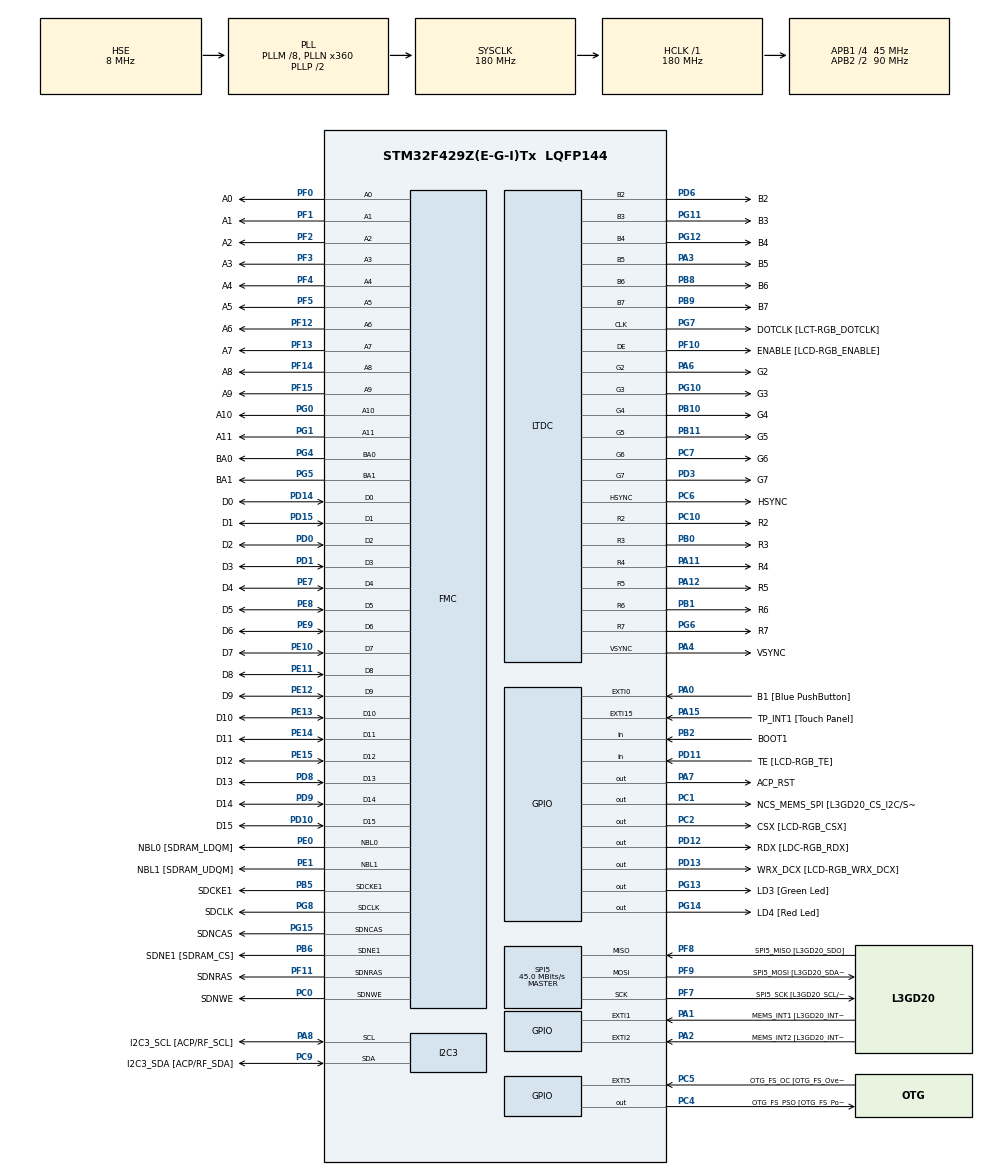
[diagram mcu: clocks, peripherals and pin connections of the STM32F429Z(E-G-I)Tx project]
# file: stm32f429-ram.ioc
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DMA2D.ColorMode=DMA2D_OUTPUT_RGB565
FMC.CASLatency1=FMC_SDRAM_CAS_LATENCY_3
FMC.ColumnBitsNumber1=FMC_SDRAM_COLUMN_BITS_NUM_8
FMC.ReadPipeDelay1=FMC_SDRAM_RPIPE_DELAY_2
FMC.ReadPipeDelay2=FMC_SDRAM_RPIPE_DELAY_2
FMC.SDClockPeriod1=FMC_SDRAM_CLOCK_PERIOD_2
FMC.SDClockPeriod2=FMC_SDRAM_CLOCK_PERIOD_2
FMC.WriteProtection1=FMC_SDRAM_WRITE_PROTECTION_ENABLE
LTDC.ActiveW=320
Mcu.Family=STM32F4
Mcu.Name=STM32F429Z(E-G-I)Tx
Mcu.Package=LQFP144
NVIC.PriorityGroup=NVIC_PRIORITYGROUP_0
PA0/WKUP.GPIO_Label=B1 [Blue PushButton]
PA0/WKUP.GPIO_ModeDefaultEXTI=GPIO_MODE_EVT_RISING
PA0/WKUP.GPIO_PuPd=GPIO_NOPULL
PA0/WKUP.Signal=GPXTI0
PA1.GPIO_Label=MEMS_INT1 [L3GD20_INT1]
PA1.GPIO_ModeDefaultEXTI=GPIO_MODE_EVT_RISING
PA1.GPIO_PuPd=GPIO_NOPULL
PA1.Signal=GPXTI1
PA11.GPIO_Label=R4
PA11.GPIO_Mode=GPIO_MODE_AF_PP
PA11.GPIO_PuPd=GPIO_NOPULL
PA11.GPIO_Speed=GPIO_SPEED_FREQ_LOW
PA11.Mode=RGB666
PA11.Signal=LTDC_R4
PA12.GPIO_Label=R5
PA12.GPIO_Mode=GPIO_MODE_AF_PP
PA12.GPIO_PuPd=GPIO_NOPULL
PA12.GPIO_Speed=GPIO_SPEED_FREQ_LOW
PA12.Mode=RGB666
PA12.Signal=LTDC_R5
PA13.GPIO_Label=SWDIO
PA13.Signal=SYS_JTMS-SWDIO
PA14.GPIO_Label=SWCLK
PA14.Signal=SYS_JTCK-SWCLK
PA15.GPIO_Label=TP_INT1 [Touch Panel]
PA15.GPIO_ModeDefaultEXTI=GPIO_MODE_EVT_RISING
PA15.GPIO_PuPd=GPIO_NOPULL
PA15.Signal=GPXTI15
PA2.GPIO_Label=MEMS_INT2 [L3GD20_INT2]
PA2.GPIO_ModeDefaultEXTI=GPIO_MODE_EVT_RISING
PA2.GPIO_PuPd=GPIO_NOPULL
PA2.Signal=GPXTI2
PA3.GPIO_Label=B5
PA3.GPIO_Mode=GPIO_MODE_AF_PP
PA3.GPIO_PuPd=GPIO_NOPULL
PA3.GPIO_Speed=GPIO_SPEED_FREQ_LOW
PA3.Mode=RGB666
PA3.Signal=LTDC_B5
PA4.GPIO_Label=VSYNC
PA4.GPIO_Mode=GPIO_MODE_AF_PP
PA4.GPIO_PuPd=GPIO_NOPULL
PA4.GPIO_Speed=GPIO_SPEED_FREQ_LOW
PA4.Mode=RGB666
PA4.Signal=LTDC_VSYNC
PA6.GPIO_Label=G2
PA6.GPIO_Mode=GPIO_MODE_AF_PP
PA6.GPIO_PuPd=GPIO_NOPULL
PA6.GPIO_Speed=GPIO_SPEED_FREQ_LOW
PA6.Mode=RGB666
PA6.Signal=LTDC_G2
PA7.GPIO_Label=ACP_RST
PA7.GPIO_Mode=GPIO_MODE_OUTPUT_PP
PA7.GPIO_PuPd=GPIO_NOPULL
PA7.GPIO_Speed=GPIO_SPEED_FREQ_LOW
PA7.Signal=GPIO_Output
PA8.GPIO_Label=I2C3_SCL [ACP/RF_SCL]
PA8.GPIO_Mode=GPIO_MODE_AF_OD
PA8.GPIO_PuPd=GPIO_NOPULL
PA8.GPIO_Speed=GPIO_SPEED_FREQ_LOW
PA8.Mode=I2C
PA8.Signal=I2C3_SCL
PB0.GPIO_Label=R3
PB0.GPIO_Mode=GPIO_MODE_AF_PP
PB0.GPIO_PuPd=GPIO_NOPULL
PB0.GPIO_Speed=GPIO_SPEED_FREQ_LOW
PB0.Mode=RGB666
PB0.Signal=LTDC_R3
PB1.GPIO_Label=R6
PB1.GPIO_Mode=GPIO_MODE_AF_PP
PB1.GPIO_PuPd=GPIO_NOPULL
PB1.GPIO_Speed=GPIO_SPEED_FREQ_LOW
PB1.Mode=RGB666
PB1.Signal=LTDC_R6
PB10.GPIO_Label=G4
PB10.GPIO_Mode=GPIO_MODE_AF_PP
PB10.GPIO_PuPd=GPIO_NOPULL
PB10.GPIO_Speed=GPIO_SPEED_FREQ_LOW
PB10.Mode=RGB666
PB10.Signal=LTDC_G4
PB11.GPIO_Label=G5
PB11.GPIO_Mode=GPIO_MODE_AF_PP
PB11.GPIO_PuPd=GPIO_NOPULL
PB11.GPIO_Speed=GPIO_SPEED_FREQ_LOW
PB11.Mode=RGB666
PB11.Signal=LTDC_G5
PB12.GPIO_Label=OTG_FS_ID
PB12.GPIO_Mode=GPIO_MODE_AF_PP
PB12.GPIO_PuPd=GPIO_NOPULL
PB12.GPIO_Speed=GPIO_SPEED_FREQ_LOW
PB12.Signal=USB_OTG_HS_ID
PB13.GPIO_Label=VBUS_FS
PB13.GPIO_Mode=GPIO_MODE_INPUT
PB13.GPIO_PuPd=GPIO_NOPULL
PB13.Signal=USB_OTG_HS_VBUS
PB14.GPIO_Label=OTG_FS_DM
PB14.GPIO_Mode=GPIO_MODE_AF_PP
PB14.GPIO_PuPd=GPIO_NOPULL
PB14.GPIO_Speed=GPIO_SPEED_FREQ_LOW
PB14.Signal=USB_OTG_HS_DM
PB15.GPIO_Label=OTG_FS_DP
PB15.GPIO_Mode=GPIO_MODE_AF_PP
PB15.GPIO_PuPd=GPIO_NOPULL
PB15.GPIO_Speed=GPIO_SPEED_FREQ_LOW
PB15.Signal=USB_OTG_HS_DP
PB2/BOOT1.GPIO_Label=BOOT1
PB2/BOOT1.GPIO_Mode=GPIO_MODE_INPUT
PB2/BOOT1.GPIO_PuPd=GPIO_NOPULL
PB2/BOOT1.Signal=GPIO_Input
PB5.GPIO_Label=SDCKE1
PB5.GPIO_Mode=GPIO_MODE_AF_PP
PB5.GPIO_PuPd=GPIO_NOPULL
PB5.GPIO_Speed=GPIO_SPEED_FREQ_VERY_HIGH
PB5.Mode=SdramChipSelect2_1
PB5.Signal=FMC_SDCKE1
PB6.GPIO_Label=SDNE1 [SDRAM_CS]
PB6.GPIO_Mode=GPIO_MODE_AF_PP
PB6.GPIO_PuPd=GPIO_NOPULL
PB6.GPIO_Speed=GPIO_SPEED_FREQ_VERY_HIGH
PB6.Mode=SdramChipSelect2_1
PB6.Signal=FMC_SDNE1
PB8.GPIO_Label=B6
PB8.GPIO_Mode=GPIO_MODE_AF_PP
PB8.GPIO_PuPd=GPIO_NOPULL
PB8.GPIO_Speed=GPIO_SPEED_FREQ_LOW
PB8.Mode=RGB666
PB8.Signal=LTDC_B6
PB9.GPIO_Label=B7
PB9.GPIO_Mode=GPIO_MODE_AF_PP
PB9.GPIO_PuPd=GPIO_NOPULL
PB9.GPIO_Speed=GPIO_SPEED_FREQ_LOW
PB9.Mode=RGB666
PB9.Signal=LTDC_B7
PC0.GPIO_Label=SDNWE
PC0.GPIO_Mode=GPIO_MODE_AF_PP
PC0.GPIO_PuPd=GPIO_NOPULL
PC0.GPIO_Speed=GPIO_SPEED_FREQ_VERY_HIGH
PC0.Signal=FMC_SDNWE
PC1.GPIO_Label=NCS_MEMS_SPI [L3GD20_CS_I2C/SPI]
PC1.GPIO_Mode=GPIO_MODE_OUTPUT_PP
PC1.GPIO_PuPd=GPIO_NOPULL
PC1.GPIO_Speed=GPIO_SPEED_FREQ_LOW
PC1.Signal=GPIO_Output
PC10.GPIO_Label=R2
PC10.GPIO_Mode=GPIO_MODE_AF_PP
PC10.GPIO_PuPd=GPIO_NOPULL
PC10.GPIO_Speed=GPIO_SPEED_FREQ_LOW
PC10.Mode=RGB666
PC10.Signal=LTDC_R2
PC14/OSC32_IN.GPIO_Label=PC14-OSC32_IN
PC14/OSC32_IN.Signal=RCC_OSC32_IN
PC15/OSC32_OUT.GPIO_Label=PC15-OSC32_OUT
PC15/OSC32_OUT.Signal=RCC_OSC32_OUT
PC2.GPIO_Label=CSX [LCD-RGB_CSX]
PC2.GPIO_Mode=GPIO_MODE_OUTPUT_PP
PC2.GPIO_PuPd=GPIO_NOPULL
PC2.GPIO_Speed=GPIO_SPEED_FREQ_LOW
PC2.Signal=GPIO_Output
PC4.GPIO_Label=OTG_FS_PSO [OTG_FS_PowerSwitchOn]
PC4.GPIO_Mode=GPIO_MODE_OUTPUT_PP
PC4.GPIO_PuPd=GPIO_NOPULL
PC4.GPIO_Speed=GPIO_SPEED_FREQ_LOW
PC4.Signal=GPIO_Output
PC5.GPIO_Label=OTG_FS_OC [OTG_FS_OverCurrent]
PC5.GPIO_ModeDefaultEXTI=GPIO_MODE_EVT_RISING
PC5.Signal=GPXTI5
PC6.GPIO_Label=HSYNC
PC6.GPIO_Mode=GPIO_MODE_AF_PP
PC6.GPIO_PuPd=GPIO_NOPULL
PC6.GPIO_Speed=GPIO_SPEED_FREQ_LOW
PC6.Mode=RGB666
PC6.Signal=LTDC_HSYNC
PC7.GPIO_Label=G6
PC7.GPIO_Mode=GPIO_MODE_AF_PP
PC7.GPIO_PuPd=GPIO_NOPULL
PC7.GPIO_Speed=GPIO_SPEED_FREQ_LOW
PC7.Mode=RGB666
PC7.Signal=LTDC_G6
PC9.GPIO_Label=I2C3_SDA [ACP/RF_SDA]
PC9.GPIO_Mode=GPIO_MODE_AF_OD
PC9.GPIO_PuPd=GPIO_NOPULL
PC9.GPIO_Speed=GPIO_SPEED_FREQ_LOW
PC9.Mode=I2C
PC9.Signal=I2C3_SDA
PD0.GPIO_Label=D2
PD0.GPIO_Mode=GPIO_MODE_AF_PP
PD0.GPIO_PuPd=GPIO_NOPULL
PD0.GPIO_Speed=GPIO_SPEED_FREQ_VERY_HIGH
PD0.Signal=FMC_D2_DA2
PD1.GPIO_Label=D3
PD1.GPIO_Mode=GPIO_MODE_AF_PP
PD1.GPIO_PuPd=GPIO_NOPULL
PD1.GPIO_Speed=GPIO_SPEED_FREQ_VERY_HIGH
PD1.Signal=FMC_D3_DA3
PD10.GPIO_Label=D15
PD10.GPIO_Mode=GPIO_MODE_AF_PP
PD10.GPIO_PuPd=GPIO_NOPULL
PD10.GPIO_Speed=GPIO_SPEED_FREQ_VERY_HIGH
PD10.Signal=FMC_D15_DA15
PD11.GPIO_Label=TE [LCD-RGB_TE]
PD11.GPIO_Mode=GPIO_MODE_INPUT
PD11.GPIO_PuPd=GPIO_NOPULL
PD11.Signal=GPIO_Input
PD12.GPIO_Label=RDX [LDC-RGB_RDX]
PD12.GPIO_Mode=GPIO_MODE_OUTPUT_PP
PD12.GPIO_PuPd=GPIO_NOPULL
PD12.GPIO_Speed=GPIO_SPEED_FREQ_LOW
PD12.Signal=GPIO_Output
PD13.GPIO_Label=WRX_DCX [LCD-RGB_WRX_DCX]
PD13.GPIO_Mode=GPIO_MODE_OUTPUT_PP
PD13.GPIO_PuPd=GPIO_NOPULL
PD13.GPIO_Speed=GPIO_SPEED_FREQ_LOW
PD13.Signal=GPIO_Output
PD14.GPIO_Label=D0
PD14.GPIO_Mode=GPIO_MODE_AF_PP
PD14.GPIO_PuPd=GPIO_NOPULL
PD14.GPIO_Speed=GPIO_SPEED_FREQ_VERY_HIGH
PD14.Signal=FMC_D0_DA0
PD15.GPIO_Label=D1
PD15.GPIO_Mode=GPIO_MODE_AF_PP
PD15.GPIO_PuPd=GPIO_NOPULL
PD15.GPIO_Speed=GPIO_SPEED_FREQ_VERY_HIGH
PD15.Signal=FMC_D1_DA1
PD3.GPIO_Label=G7
PD3.GPIO_Mode=GPIO_MODE_AF_PP
PD3.GPIO_PuPd=GPIO_NOPULL
PD3.GPIO_Speed=GPIO_SPEED_FREQ_LOW
PD3.Mode=RGB666
PD3.Signal=LTDC_G7
PD6.GPIO_Label=B2
PD6.GPIO_Mode=GPIO_MODE_AF_PP
PD6.GPIO_PuPd=GPIO_NOPULL
PD6.GPIO_Speed=GPIO_SPEED_FREQ_LOW
PD6.Mode=RGB666
PD6.Signal=LTDC_B2
PD8.GPIO_Label=D13
PD8.GPIO_Mode=GPIO_MODE_AF_PP
PD8.GPIO_PuPd=GPIO_NOPULL
PD8.GPIO_Speed=GPIO_SPEED_FREQ_VERY_HIGH
PD8.Signal=FMC_D13_DA13
PD9.GPIO_Label=D14
PD9.GPIO_Mode=GPIO_MODE_AF_PP
PD9.GPIO_PuPd=GPIO_NOPULL
PD9.GPIO_Speed=GPIO_SPEED_FREQ_VERY_HIGH
PD9.Signal=FMC_D14_DA14
PE0.GPIO_Label=NBL0 [SDRAM_LDQM]
PE0.GPIO_Mode=GPIO_MODE_AF_PP
PE0.GPIO_PuPd=GPIO_NOPULL
PE0.GPIO_Speed=GPIO_SPEED_FREQ_VERY_HIGH
PE0.Signal=FMC_NBL0
PE1.GPIO_Label=NBL1 [SDRAM_UDQM]
PE1.GPIO_Mode=GPIO_MODE_AF_PP
PE1.GPIO_PuPd=GPIO_NOPULL
PE1.GPIO_Speed=GPIO_SPEED_FREQ_VERY_HIGH
PE1.Signal=FMC_NBL1
PE10.GPIO_Label=D7
PE10.GPIO_Mode=GPIO_MODE_AF_PP
PE10.GPIO_PuPd=GPIO_NOPULL
PE10.GPIO_Speed=GPIO_SPEED_FREQ_VERY_HIGH
PE10.Signal=FMC_D7_DA7
PE11.GPIO_Label=D8
PE11.GPIO_Mode=GPIO_MODE_AF_PP
PE11.GPIO_PuPd=GPIO_NOPULL
PE11.GPIO_Speed=GPIO_SPEED_FREQ_VERY_HIGH
PE11.Signal=FMC_D8_DA8
PE12.GPIO_Label=D9
PE12.GPIO_Mode=GPIO_MODE_AF_PP
PE12.GPIO_PuPd=GPIO_NOPULL
PE12.GPIO_Speed=GPIO_SPEED_FREQ_VERY_HIGH
PE12.Signal=FMC_D9_DA9
PE13.GPIO_Label=D10
PE13.GPIO_Mode=GPIO_MODE_AF_PP
PE13.GPIO_PuPd=GPIO_NOPULL
PE13.GPIO_Speed=GPIO_SPEED_FREQ_VERY_HIGH
PE13.Signal=FMC_D10_DA10
PE14.GPIO_Label=D11
PE14.GPIO_Mode=GPIO_MODE_AF_PP
PE14.GPIO_PuPd=GPIO_NOPULL
PE14.GPIO_Speed=GPIO_SPEED_FREQ_VERY_HIGH
PE14.Signal=FMC_D11_DA11
PE15.GPIO_Label=D12
PE15.GPIO_Mode=GPIO_MODE_AF_PP
PE15.GPIO_PuPd=GPIO_NOPULL
PE15.GPIO_Speed=GPIO_SPEED_FREQ_VERY_HIGH
PE15.Signal=FMC_D12_DA12
PE7.GPIO_Label=D4
PE7.GPIO_Mode=GPIO_MODE_AF_PP
PE7.GPIO_PuPd=GPIO_NOPULL
PE7.GPIO_Speed=GPIO_SPEED_FREQ_VERY_HIGH
PE7.Signal=FMC_D4_DA4
PE8.GPIO_Label=D5
PE8.GPIO_Mode=GPIO_MODE_AF_PP
PE8.GPIO_PuPd=GPIO_NOPULL
PE8.GPIO_Speed=GPIO_SPEED_FREQ_VERY_HIGH
PE8.Signal=FMC_D5_DA5
PE9.GPIO_Label=D6
PE9.GPIO_Mode=GPIO_MODE_AF_PP
PE9.GPIO_PuPd=GPIO_NOPULL
PE9.GPIO_Speed=GPIO_SPEED_FREQ_VERY_HIGH
PE9.Signal=FMC_D6_DA6
PF0.GPIO_Label=A0
PF0.GPIO_Mode=GPIO_MODE_AF_PP
PF0.GPIO_PuPd=GPIO_NOPULL
PF0.GPIO_Speed=GPIO_SPEED_FREQ_VERY_HIGH
PF0.Signal=FMC_A0
PF1.GPIO_Label=A1
PF1.GPIO_Mode=GPIO_MODE_AF_PP
PF1.GPIO_PuPd=GPIO_NOPULL
PF1.GPIO_Speed=GPIO_SPEED_FREQ_VERY_HIGH
PF1.Signal=FMC_A1
PF10.GPIO_Label=ENABLE [LCD-RGB_ENABLE]
PF10.GPIO_Mode=GPIO_MODE_AF_PP
PF10.GPIO_PuPd=GPIO_NOPULL
PF10.GPIO_Speed=GPIO_SPEED_FREQ_LOW
PF10.Mode=RGB666
PF10.Signal=LTDC_DE
PF11.GPIO_Label=SDNRAS
PF11.GPIO_Mode=GPIO_MODE_AF_PP
PF11.GPIO_PuPd=GPIO_NOPULL
PF11.GPIO_Speed=GPIO_SPEED_FREQ_VERY_HIGH
PF11.Signal=FMC_SDNRAS
PF12.GPIO_Label=A6
PF12.GPIO_Mode=GPIO_MODE_AF_PP
PF12.GPIO_PuPd=GPIO_NOPULL
PF12.GPIO_Speed=GPIO_SPEED_FREQ_VERY_HIGH
PF12.Signal=FMC_A6
PF13.GPIO_Label=A7
PF13.GPIO_Mode=GPIO_MODE_AF_PP
PF13.GPIO_PuPd=GPIO_NOPULL
PF13.GPIO_Speed=GPIO_SPEED_FREQ_VERY_HIGH
PF13.Signal=FMC_A7
PF14.GPIO_Label=A8
PF14.GPIO_Mode=GPIO_MODE_AF_PP
PF14.GPIO_PuPd=GPIO_NOPULL
PF14.GPIO_Speed=GPIO_SPEED_FREQ_VERY_HIGH
PF14.Signal=FMC_A8
PF15.GPIO_Label=A9
PF15.GPIO_Mode=GPIO_MODE_AF_PP
PF15.GPIO_PuPd=GPIO_NOPULL
PF15.GPIO_Speed=GPIO_SPEED_FREQ_VERY_HIGH
PF15.Signal=FMC_A9
PF2.GPIO_Label=A2
PF2.GPIO_Mode=GPIO_MODE_AF_PP
PF2.GPIO_PuPd=GPIO_NOPULL
PF2.GPIO_Speed=GPIO_SPEED_FREQ_VERY_HIGH
PF2.Signal=FMC_A2
PF3.GPIO_Label=A3
PF3.GPIO_Mode=GPIO_MODE_AF_PP
PF3.GPIO_PuPd=GPIO_NOPULL
PF3.GPIO_Speed=GPIO_SPEED_FREQ_VERY_HIGH
PF3.Signal=FMC_A3
PF4.GPIO_Label=A4
PF4.GPIO_Mode=GPIO_MODE_AF_PP
PF4.GPIO_PuPd=GPIO_NOPULL
PF4.GPIO_Speed=GPIO_SPEED_FREQ_VERY_HIGH
PF4.Signal=FMC_A4
PF5.GPIO_Label=A5
PF5.GPIO_Mode=GPIO_MODE_AF_PP
PF5.GPIO_PuPd=GPIO_NOPULL
PF5.GPIO_Speed=GPIO_SPEED_FREQ_VERY_HIGH
PF5.Signal=FMC_A5
PF7.GPIO_Label=SPI5_SCK [L3GD20_SCL/SPC]
PF7.GPIO_Mode=GPIO_MODE_AF_PP
PF7.GPIO_PuPd=GPIO_NOPULL
PF7.GPIO_Speed=GPIO_SPEED_FREQ_LOW
PF7.Mode=Full_Duplex_Master
PF7.Signal=SPI5_SCK
PF8.GPIO_Label=SPI5_MISO [L3GD20_SDO]
PF8.GPIO_Mode=GPIO_MODE_AF_PP
PF8.GPIO_PuPd=GPIO_NOPULL
PF8.GPIO_Speed=GPIO_SPEED_FREQ_LOW
PF8.Mode=Full_Duplex_Master
PF8.Signal=SPI5_MISO
PF9.GPIO_Label=SPI5_MOSI [L3GD20_SDA/SDI/SDO]
PF9.GPIO_Mode=GPIO_MODE_AF_PP
PF9.GPIO_PuPd=GPIO_NOPULL
PF9.GPIO_Speed=GPIO_SPEED_FREQ_LOW
PF9.Mode=Full_Duplex_Master
PF9.Signal=SPI5_MOSI
PG0.GPIO_Label=A10
PG0.GPIO_Mode=GPIO_MODE_AF_PP
PG0.GPIO_PuPd=GPIO_NOPULL
PG0.GPIO_Speed=GPIO_SPEED_FREQ_VERY_HIGH
PG0.Signal=FMC_A10
PG1.GPIO_Label=A11
PG1.GPIO_Mode=GPIO_MODE_AF_PP
PG1.GPIO_PuPd=GPIO_NOPULL
PG1.GPIO_Speed=GPIO_SPEED_FREQ_VERY_HIGH
PG1.Signal=FMC_A11
PG10.GPIO_Label=G3
PG10.GPIO_Mode=GPIO_MODE_AF_PP
PG10.GPIO_PuPd=GPIO_NOPULL
PG10.GPIO_Speed=GPIO_SPEED_FREQ_LOW
PG10.Mode=RGB666
PG10.Signal=LTDC_G3
PG11.GPIO_Label=B3
PG11.GPIO_Mode=GPIO_MODE_AF_PP
PG11.GPIO_PuPd=GPIO_NOPULL
PG11.GPIO_Speed=GPIO_SPEED_FREQ_LOW
PG11.Mode=RGB666
PG11.Signal=LTDC_B3
PG12.GPIO_Label=B4
PG12.GPIO_Mode=GPIO_MODE_AF_PP
PG12.GPIO_PuPd=GPIO_NOPULL
PG12.GPIO_Speed=GPIO_SPEED_FREQ_LOW
PG12.Mode=RGB666
PG12.Signal=LTDC_B4
PG13.GPIO_Label=LD3 [Green Led]
PG13.GPIO_Mode=GPIO_MODE_OUTPUT_PP
PG13.GPIO_PuPd=GPIO_NOPULL
PG13.GPIO_Speed=GPIO_SPEED_FREQ_LOW
PG13.Signal=GPIO_Output
PG14.GPIO_Label=LD4 [Red Led]
PG14.GPIO_Mode=GPIO_MODE_OUTPUT_PP
PG14.GPIO_PuPd=GPIO_NOPULL
PG14.GPIO_Speed=GPIO_SPEED_FREQ_LOW
PG14.Signal=GPIO_Output
PG15.GPIO_Label=SDNCAS
PG15.GPIO_Mode=GPIO_MODE_AF_PP
PG15.GPIO_PuPd=GPIO_NOPULL
PG15.GPIO_Speed=GPIO_SPEED_FREQ_VERY_HIGH
PG15.Signal=FMC_SDNCAS
PG4.GPIO_Label=BA0
PG4.GPIO_Mode=GPIO_MODE_AF_PP
PG4.GPIO_PuPd=GPIO_NOPULL
PG4.GPIO_Speed=GPIO_SPEED_FREQ_VERY_HIGH
PG4.Signal=FMC_A14_BA0
PG5.GPIO_Label=BA1
PG5.GPIO_Mode=GPIO_MODE_AF_PP
PG5.GPIO_PuPd=GPIO_NOPULL
PG5.GPIO_Speed=GPIO_SPEED_FREQ_VERY_HIGH
PG5.Signal=FMC_A15_BA1
PG6.GPIO_Label=R7
PG6.GPIO_Mode=GPIO_MODE_AF_PP
PG6.GPIO_PuPd=GPIO_NOPULL
PG6.GPIO_Speed=GPIO_SPEED_FREQ_LOW
PG6.Mode=RGB666
PG6.Signal=LTDC_R7
PG7.GPIO_Label=DOTCLK [LCT-RGB_DOTCLK]
PG7.GPIO_Mode=GPIO_MODE_AF_PP
PG7.GPIO_PuPd=GPIO_NOPULL
PG7.GPIO_Speed=GPIO_SPEED_FREQ_LOW
PG7.Mode=RGB666
PG7.Signal=LTDC_CLK
PG8.GPIO_Label=SDCLK
PG8.GPIO_Mode=GPIO_MODE_AF_PP
PG8.GPIO_PuPd=GPIO_NOPULL
PG8.GPIO_Speed=GPIO_SPEED_FREQ_VERY_HIGH
PG8.Signal=FMC_SDCLK
PH0/OSC_IN.GPIO_Label=PH0-OSC_IN
PH0/OSC_IN.Mode=HSE-External-Clock-Source
PH0/OSC_IN.Signal=RCC_OSC_IN
PH1/OSC_OUT.GPIO_Label=PH1-OSC_OUT
PH1/OSC_OUT.Mode=HSE-External-Clock-Source
PH1/OSC_OUT.Signal=RCC_OSC_OUT
ProjectManager.HeapSize=0x200
ProjectManager.StackSize=0x400
ProjectManager.TargetToolchain=SW4STM32
RCC.48MHZClocksFreq_Value=51428571.428571425
RCC.AHBFreq_Value=180000000
RCC.APB1CLKDivider=RCC_HCLK_DIV4
RCC.APB1Freq_Value=45000000
RCC.APB1TimFreq_Value=90000000
RCC.APB2CLKDivider=RCC_HCLK_DIV2
RCC.APB2Freq_Value=90000000
RCC.APB2TimFreq_Value=180000000
RCC.CortexFreq_Value=180000000
RCC.HCLKFreq_Value=180000000
RCC.HSE_VALUE=8000000
RCC.HSI_VALUE=16000000
RCC.LSE_VALUE=32768
RCC.PLLM=8
RCC.PLLN=360
RCC.PLLQ=7
RCC.PLLSAIN=432
RCC.PLLSourceVirtual=RCC_PLLSOURCE_HSE
RCC.SYSCLKFreq_VALUE=180000000
RCC.SYSCLKSource=RCC_SYSCLKSOURCE_PLLCLK
RCC.VCOOutputFreq_Value=360000000
SH.FMC_A0.0=FMC_A0,12b-sda1
SH.FMC_A1.0=FMC_A1,12b-sda1
SH.FMC_A10.0=FMC_A10,12b-sda1
SH.FMC_A11.0=FMC_A11,12b-sda1
SH.FMC_A14_BA0.0=FMC_BA0,FourSdramBanks1
SH.FMC_A15_BA1.0=FMC_BA1,FourSdramBanks1
SH.FMC_A2.0=FMC_A2,12b-sda1
SH.FMC_A3.0=FMC_A3,12b-sda1
SH.FMC_A4.0=FMC_A4,12b-sda1
SH.FMC_A5.0=FMC_A5,12b-sda1
SH.FMC_A6.0=FMC_A6,12b-sda1
SH.FMC_A7.0=FMC_A7,12b-sda1
SH.FMC_A8.0=FMC_A8,12b-sda1
SH.FMC_A9.0=FMC_A9,12b-sda1
SH.FMC_D0_DA0.0=FMC_D0,sd-16b-d1
SH.FMC_D10_DA10.0=FMC_D10,sd-16b-d1
SH.FMC_D11_DA11.0=FMC_D11,sd-16b-d1
SH.FMC_D12_DA12.0=FMC_D12,sd-16b-d1
SH.FMC_D13_DA13.0=FMC_D13,sd-16b-d1
SH.FMC_D14_DA14.0=FMC_D14,sd-16b-d1
SH.FMC_D15_DA15.0=FMC_D15,sd-16b-d1
SH.FMC_D1_DA1.0=FMC_D1,sd-16b-d1
SH.FMC_D2_DA2.0=FMC_D2,sd-16b-d1
SH.FMC_D3_DA3.0=FMC_D3,sd-16b-d1
SH.FMC_D4_DA4.0=FMC_D4,sd-16b-d1
SH.FMC_D5_DA5.0=FMC_D5,sd-16b-d1
SH.FMC_D6_DA6.0=FMC_D6,sd-16b-d1
SH.FMC_D7_DA7.0=FMC_D7,sd-16b-d1
SH.FMC_D8_DA8.0=FMC_D8,sd-16b-d1
SH.FMC_D9_DA9.0=FMC_D9,sd-16b-d1
SH.FMC_NBL0.0=FMC_NBL0,Sd2ByteEnable1
SH.FMC_NBL1.0=FMC_NBL1,Sd2ByteEnable1
SH.FMC_SDCLK.0=FMC_SDCLK,12b-sda1
SH.FMC_SDNCAS.0=FMC_SDNCAS,12b-sda1
SH.FMC_SDNRAS.0=FMC_SDNRAS,12b-sda1
SH.FMC_SDNWE.0=FMC_SDNWE,12b-sda1
SPI5.BaudRatePrescaler=SPI_BAUDRATEPRESCALER_2
SPI5.CalculateBaudRate=45.0 MBits/s
SPI5.Direction=SPI_DIRECTION_2LINES
SPI5.Mode=SPI_MODE_MASTER
SPI5.VirtualType=VM_MASTER
VP_DMA2D_VS_DMA2D.Mode=DMA2D_Activate
board=STM32F429I-DISCO

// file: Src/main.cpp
/**
  ******************************************************************************
  * File Name          : main.c
  * Description        : Main program body
  ******************************************************************************
  *
  * COPYRIGHT(c) 2017 STMicroelectronics
  *
  * Redistribution and use in source and binary forms, with or without modification,
  * are permitted provided that the following conditions are met:
  *   1. Redistributions of source code must retain the above copyright notice,
  *      this list of conditions and the following disclaimer.
  *   2. Redistributions in binary form must reproduce the above copyright notice,
  *      this list of conditions and the following disclaimer in the documentation
  *      and/or other materials provided with the distribution.
  *   3. Neither the name of STMicroelectronics nor the names of its contributors
  *      may be used to endorse or promote products derived from this software
  *      without specific prior written permission.
  *
  * THIS SOFTWARE IS PROVIDED BY THE COPYRIGHT HOLDERS AND CONTRIBUTORS "AS IS"
  * AND ANY EXPRESS OR IMPLIED WARRANTIES, INCLUDING, BUT NOT LIMITED TO, THE
  * IMPLIED WARRANTIES OF MERCHANTABILITY AND FITNESS FOR A PARTICULAR PURPOSE ARE
  * DISCLAIMED. IN NO EVENT SHALL THE COPYRIGHT HOLDER OR CONTRIBUTORS BE LIABLE
  * FOR ANY DIRECT, INDIRECT, INCIDENTAL, SPECIAL, EXEMPLARY, OR CONSEQUENTIAL
  * DAMAGES (INCLUDING, BUT NOT LIMITED TO, PROCUREMENT OF SUBSTITUTE GOODS OR
  * SERVICES; LOSS OF USE, DATA, OR PROFITS; OR BUSINESS INTERRUPTION) HOWEVER
  * CAUSED AND ON ANY THEORY OF LIABILITY, WHETHER IN CONTRACT, STRICT LIABILITY,
  * OR TORT (INCLUDING NEGLIGENCE OR OTHERWISE) ARISING IN ANY WAY OUT OF THE USE
  * OF THIS SOFTWARE, EVEN IF ADVISED OF THE POSSIBILITY OF SUCH DAMAGE.
  *
  ******************************************************************************
  */
#include "main.h"
#include "stm32f4xx_hal.h"

/* USER CODE BEGIN Includes */
#include "stm32f4xx_hal_ltdc.h"
#include "stm32f429i_discovery_lcd.h"
#include "stm32f429i_discovery_sdram.h"
#include "stm32f429i_discovery.h"

#include "PAW_Vector.h"
#include "PAW_Matrix.h"
#include "PAW_Color.h"
#include "PAW_Primitive.h"
#include "PAW_Figure.h"
#include "PAW_Scene.h"
#include <cmath>
#include <vector>

/* USER CODE END Includes */

DMA2D_HandleTypeDef hdma2d;

I2C_HandleTypeDef hi2c3;

LTDC_HandleTypeDef hltdc;

SPI_HandleTypeDef hspi5;

SDRAM_HandleTypeDef hsdram1;

/* USER CODE BEGIN PV */
/* Private variables ---------------------------------------------------------*/

/* USER CODE END PV */

void SystemClock_Config(void);
void Error_Handler(void);
static void MX_GPIO_Init(void);
static void MX_DMA2D_Init(void);
static void MX_FMC_Init(void);
static void MX_I2C3_Init(void);
static void MX_LTDC_Init(void);
static void MX_SPI5_Init(void);

/* USER CODE BEGIN PFP */
/* Private function prototypes -----------------------------------------------*/

/* USER CODE END PFP */

/* USER CODE BEGIN 0 */

/* *
  * @brief  HAL SDRAM State structure definition
  * /
typedef enum
{
  HAL_SDRAM_STATE_RESET             = 0x00U,  / *!< SDRAM not yet initialized or disabled * /
  HAL_SDRAM_STATE_READY             = 0x01U,  / *!< SDRAM initialized and ready for use   * /
  HAL_SDRAM_STATE_BUSY              = 0x02U,  / *!< SDRAM internal process is ongoing     * /
  HAL_SDRAM_STATE_ERROR             = 0x03U,  / *!< SDRAM error state                     * /
  HAL_SDRAM_STATE_WRITE_PROTECTED   = 0x04U,  / *!< SDRAM device write protected          * /
  HAL_SDRAM_STATE_PRECHARGED        = 0x05U   / *!< SDRAM device precharged               * /

}HAL_SDRAM_StateTypeDef; */

void led_sdram_reset(void)
{
	  if(hsdram1.State == HAL_SDRAM_STATE_RESET)
	  {
		  HAL_GPIO_WritePin(GPIOG, GPIO_PIN_13, GPIO_PIN_SET);
		  HAL_Delay(250);
		  HAL_GPIO_WritePin(GPIOG, GPIO_PIN_13, GPIO_PIN_RESET);
		  HAL_Delay(250);
		  HAL_GPIO_WritePin(GPIOG, GPIO_PIN_13, GPIO_PIN_SET);
		  HAL_Delay(250);
		  HAL_GPIO_WritePin(GPIOG, GPIO_PIN_13, GPIO_PIN_RESET);
		  HAL_Delay(250);
	  }
}

void led_sdram_ready()
{
	  if(hsdram1.State == HAL_SDRAM_STATE_READY)
	  {
		  HAL_GPIO_WritePin(GPIOG, GPIO_PIN_13, GPIO_PIN_SET);
		  HAL_Delay(250);
		  HAL_GPIO_WritePin(GPIOG, GPIO_PIN_13, GPIO_PIN_RESET);
		  HAL_GPIO_WritePin(GPIOG, GPIO_PIN_14, GPIO_PIN_SET);
		  HAL_Delay(250);
		  HAL_GPIO_WritePin(GPIOG, GPIO_PIN_14, GPIO_PIN_RESET);
		  HAL_GPIO_WritePin(GPIOG, GPIO_PIN_13, GPIO_PIN_SET);
		  HAL_Delay(250);
		  HAL_GPIO_WritePin(GPIOG, GPIO_PIN_13, GPIO_PIN_RESET);
		  HAL_GPIO_WritePin(GPIOG, GPIO_PIN_14, GPIO_PIN_SET);
		  HAL_Delay(250);
		  HAL_GPIO_WritePin(GPIOG, GPIO_PIN_14, GPIO_PIN_RESET);
	  }
}

void led_sdram_busy()
{
	  if(hsdram1.State == HAL_SDRAM_STATE_BUSY)
	  {
		  HAL_GPIO_WritePin(GPIOG, GPIO_PIN_13, GPIO_PIN_SET);
		  HAL_Delay(250);
		  HAL_GPIO_WritePin(GPIOG, GPIO_PIN_14, GPIO_PIN_SET);
		  HAL_Delay(250);
		  HAL_GPIO_WritePin(GPIOG, GPIO_PIN_14, GPIO_PIN_RESET);
		  HAL_Delay(250);
		  HAL_GPIO_WritePin(GPIOG, GPIO_PIN_14, GPIO_PIN_SET);
		  HAL_Delay(250);
		  HAL_GPIO_WritePin(GPIOG, GPIO_PIN_14, GPIO_PIN_RESET);
		  HAL_GPIO_WritePin(GPIOG, GPIO_PIN_13, GPIO_PIN_RESET);
	  }
}

void led_sdram_error()
{
	  if(hsdram1.State == HAL_SDRAM_STATE_ERROR)
	  {
		  HAL_GPIO_WritePin(GPIOG, GPIO_PIN_14, GPIO_PIN_SET);
		  HAL_Delay(250);
		  HAL_GPIO_WritePin(GPIOG, GPIO_PIN_14, GPIO_PIN_RESET);
		  HAL_Delay(250);
		  HAL_GPIO_WritePin(GPIOG, GPIO_PIN_14, GPIO_PIN_SET);
		  HAL_Delay(250);
		  HAL_GPIO_WritePin(GPIOG, GPIO_PIN_14, GPIO_PIN_RESET);
		  HAL_Delay(250);
	  }
}

void led_sdram_write_proteced()
{
	  if(hsdram1.State == HAL_SDRAM_STATE_WRITE_PROTECTED)
	  {
		  HAL_GPIO_WritePin(GPIOG, GPIO_PIN_13, GPIO_PIN_SET);
		  HAL_Delay(1000);
		  HAL_GPIO_WritePin(GPIOG, GPIO_PIN_13, GPIO_PIN_RESET);
	  }
}

void led_sdram_precharged()
{
	  if(hsdram1.State == HAL_SDRAM_STATE_PRECHARGED)
	  {
		  HAL_GPIO_WritePin(GPIOG, GPIO_PIN_13, GPIO_PIN_SET);
		  HAL_GPIO_WritePin(GPIOG, GPIO_PIN_14, GPIO_PIN_SET);
		  HAL_Delay(250);
		  HAL_GPIO_WritePin(GPIOG, GPIO_PIN_13, GPIO_PIN_RESET);
		  HAL_GPIO_WritePin(GPIOG, GPIO_PIN_14, GPIO_PIN_RESET);
		  HAL_Delay(250);
		  HAL_GPIO_WritePin(GPIOG, GPIO_PIN_13, GPIO_PIN_SET);
		  HAL_GPIO_WritePin(GPIOG, GPIO_PIN_14, GPIO_PIN_SET);
		  HAL_Delay(250);
		  HAL_GPIO_WritePin(GPIOG, GPIO_PIN_13, GPIO_PIN_RESET);
		  HAL_GPIO_WritePin(GPIOG, GPIO_PIN_14, GPIO_PIN_RESET);
		  HAL_Delay(250);
	  }
}

void led_sdram_check()
{
    HAL_GPIO_WritePin(GPIOG, GPIO_PIN_13, GPIO_PIN_RESET);
    HAL_GPIO_WritePin(GPIOG, GPIO_PIN_14, GPIO_PIN_RESET);
	led_sdram_reset(); // G:*-*- R:----
	led_sdram_ready(); // G:*-*- R:-*-*
	led_sdram_busy(); // G:**** R:-*-*
	led_sdram_error(); // G:---- R:*-*-
	led_sdram_write_proteced(); // G:**** R:----
	led_sdram_precharged(); // G:*-*- R:*-*-
}

void PAW_MakeStarFromFigure(PAW_Figure &this_figure, PAW_Vector position, float radius, PAW_Color color)
{
	  PAW_Vector gw1(0,radius,0,1);
	  PAW_Vector gw2(radius*sqrt(3)/2,radius/2,0,1);
	  PAW_Vector gw3(-radius*sqrt(3)/2,radius/2,0,1);
	  PAW_Line line1(position-gw1, position+gw1, color);
	  PAW_Line line2(position-gw2, position+gw2, color);
	  PAW_Line line3(position-gw3, position+gw3, color);
	  this_figure.push(line1);
	  this_figure.push(line2);
	  this_figure.push(line3);
}

void PAW_MakeDonutFromFigure(PAW_Figure &this_figure, PAW_Vector position, float radius1, float radius2, PAW_Color color)
{
	  PAW_Circle circle1(position, radius1, false, color);
	  PAW_Circle circle2(position, radius2, false, color);
	  this_figure.push(circle1);
	  this_figure.push(circle2);
}

void PAW_MakeFeatherFromFigure(PAW_Figure &this_figure)
{
	PAW_Circle big_cir1(PAW_Vector(120, 90, 0, 1), 35, true, PAW_Color(255, 0, 255, 0));
	PAW_Circle big_cir2(PAW_Vector(120, 90, 0, 1), 20, true, PAW_Color(255, 0, 0, 255));

	PAW_Circle mid_cir1(PAW_Vector(120, 90+50, 0, 1), 30, true, PAW_Color(255, 0, 255, 0));
	PAW_Circle mid_cir2(PAW_Vector(120, 90+50, 0, 1), 15, true, PAW_Color(255, 0, 0, 255));

	PAW_Circle s_cir1(PAW_Vector(120, 90+50+40, 0, 1), 25, true, PAW_Color(255, 0, 255, 0));
	PAW_Circle s_cir2(PAW_Vector(120, 90+50+40, 0, 1), 15, true, PAW_Color(255, 0, 0, 255));
	PAW_Circle s_cir3(PAW_Vector(120, 90+50+40+30, 0, 1), 20, true, PAW_Color(255, 0, 255, 0));
	PAW_Circle s_cir4(PAW_Vector(120, 90+50+40+30, 0, 1), 10, true, PAW_Color(255, 0, 0, 255));
	PAW_Circle s_cir5(PAW_Vector(120, 90+50+40+30+30, 0, 1), 20, true, PAW_Color(255, 0, 255, 0));
	PAW_Circle s_cir6(PAW_Vector(120, 90+50+40+30+30, 0, 1), 10, true, PAW_Color(255, 0, 0, 255));

	this_figure.push(big_cir1);
	this_figure.push(big_cir2);
	this_figure.push(mid_cir1);
	this_figure.push(mid_cir2);
	this_figure.push(s_cir1);
	this_figure.push(s_cir2);
	this_figure.push(s_cir3);
	this_figure.push(s_cir4);
	this_figure.push(s_cir5);
	this_figure.push(s_cir6);
}

#define PAW_LCD_X_SIZE 240
#define PAW_LCD_Y_SIZE 320

class PAW_Interfece
{
public:
//	uint8_t buffer_width = 16;
//	uint8_t buffer_heigth = 16;
//	uint8_t buffer_size = 256;

	uint32_t adress_of_layer;
	uint32_t temp_adress;

//	uint8_t number_of_fields = 300;

	uint32_t * buffer;

	PAW_Interfece(uint32_t aadress_of_layer):
		adress_of_layer(aadress_of_layer),
		temp_adress(0)
	{
		buffer = new uint32_t[256];
	}

	void load_buffer(uint8_t number)
	{
		temp_adress = 0xD0000000 + adress_of_layer + number*256;
		HAL_SDRAM_Read_32b( &hsdram1, (uint32_t *)temp_adress, buffer,256);
	}

	void set_color_buffer(uint16_t num)
	{
		for(uint16_t i = 0; i < 256; i++)
			buffer[i] = 0xff000000 +0x00100000*num + 0x00000001*i + 0x00000100*(255-i);
	}

	void save_buffer(uint8_t number)
	{
//		temp_adress = SDRAM_DEVICE_ADDR + adress_of_layer + number*0x100;
		temp_adress = 0xD0000000 + adress_of_layer + number*256;
		HAL_SDRAM_Write_32b( &hsdram1, (uint32_t *)temp_adress, buffer, 256);
	}

	void get_pixels_from_scene(PAW_Scene ascene, uint16_t number_of_buffer)
	{
		uint32_t result;

		int i = 265;
		while(i)
		{
			i = i-1;
			buffer[i] = ascene.background.fullColor;
		}

		for(uint16_t x = ascene.figs.size(); x >= 0; x--)
			for(uint16_t y = ascene.figs[x].form.size(); y >= 0; y--)
				for(uint16_t i = 0; i < 16; i++)
					for(uint16_t j = 0; j < 16; j++) {
						result = ascene.figs[x].form[y]->send_to_ram(i,j);
						if (result - ascene.background.fullColor) buffer[i*16+j] = result;
					}
	}

	/*
	void reset_ram()
	{

		uint16_t x_buffers = (uint16_t)(PAW_LCD_X_SIZE/buffer_width);
		uint16_t y_buffers = (uint16_t)(PAW_LCD_Y_SIZE/buffer_heigth);
		for(uint16_t i = 0; i < (y_buffers*x_buffers); i++)
			buffer[i] = 0xffffffff;
		 for(uint16_t k = 0; k < x_buffers; k++) {
		  for(uint16_t l = 0; l < y_buffers; l++) {
		   temp_adress = SDRAM_DEVICE_ADDR + adress_of_layer + (k*l+k)*buffer_size;
		   HAL_SDRAM_Write_32b( &hsdram1, (uint32_t *)temp_adress, buffer, buffer_size);
		  }
	     }
	}*/

	void show_snap()
	{
		for(uint16_t k = 0; k < 15; k++) {
		 set_color_buffer(k);
		 for(uint16_t l = 0; l < 20; l++) {
		  save_buffer(l+k*20);
		  load_buffer(l+k*20);
		  for(uint16_t i = 0; i < 16; i++) {
		   for(uint16_t j = 0; j < 16; j++) {
		    BSP_LCD_DrawPixel(k*16+i,l*16+j,buffer[i*16+j]);
	 	   }
		  }
		 }
	    }
	}
};

/* USER CODE END 0 */

int main(void)
{

  /* MCU Configuration----------------------------------------------------------*/

  /* Reset of all peripherals, Initializes the Flash interface and the Systick. */
  HAL_Init();

  /* Configure the system clock */
  SystemClock_Config();

  /* Initialize all configured peripherals */
  MX_GPIO_Init();
  MX_DMA2D_Init();
  MX_FMC_Init();
  MX_I2C3_Init();
  MX_LTDC_Init();
  MX_SPI5_Init();

  /* USER CODE BEGIN 2 */

  BSP_LCD_Init();
  BSP_LCD_LayerDefaultInit(LCD_FOREGROUND_LAYER, LCD_FRAME_BUFFER);
  BSP_LCD_SelectLayer(LCD_FOREGROUND_LAYER);
  BSP_LCD_DisplayOn();
  BSP_LCD_Clear(LCD_COLOR_WHITE);

  BSP_SDRAM_Init();
//  led_sdram_check();

  /* USER CODE END 2 */

  /* Infinite loop */
  /* USER CODE BEGIN WHILE */

  //*******//
  // SDRAM //
  //*******//

//  PAW_Interfece interface(0x00012C00*5);
//  interface.show_snap();

//  uint32_t buff = 0xFF000000;
//  for(uint32_t i = 0x000000; i<0x200000; i+=0x000001) {
//	  buff = 0xff000000+i;
//	  HAL_SDRAM_Write_32b( &hsdram1, (uint32_t *)(i+0xD0000000), &buff, 1);
//  }

  //*****//
  // PAW //
  //*****//
  PAW_Scene superscena(PAW_Color(0xff,50,0,200));

  PAW_Figure f1, f2, f3;
  PAW_MakeFeatherFromFigure(f1);
  PAW_MakeFeatherFromFigure(f2);
  PAW_MakeFeatherFromFigure(f3);
  superscena.push(f1);
  superscena.push(f2);
  superscena.push(f3);
  PAW_Vector temp1(2,2, 0, 0);
  PAW_Vector temp2(3,3, 0, 0);

  PAW_Figure paw; //PAW
  paw.push(PAW_Line(PAW_Vector(120,200,0,1), PAW_Vector(140,160,0,1), PAW_Color(255,255,211,0)));
  paw.push(PAW_Line(PAW_Vector(120,200,0,1), PAW_Vector(100,160,0,1), PAW_Color(255,255,211,0)));
  paw.push(PAW_Circle(PAW_Vector(120,290,0,1), 50, true, PAW_Color(200, 62, 209, 0)));
  paw.push(PAW_Circle(PAW_Vector(120,190,0,1), 20, true, PAW_Color(200, 62, 209, 0)));

  for(int i = 110; i < 130; i++)
  {
	  paw.push(PAW_Line(PAW_Vector(i, 200, 0, 1), PAW_Vector(i, 290, 0, 1), PAW_Color(200, 62, 209, 0)));
  }

  paw.push(PAW_Circle(PAW_Vector(115, 190, 0, 1), 2, true, PAW_Color(255, 0, 0, 50)));
  paw.push(PAW_Circle(PAW_Vector(125, 190, 0, 1), 2, true, PAW_Color(255, 0, 0, 50)));
  paw.push(PAW_Circle(PAW_Vector(120, 200, 0, 1), 3, true, PAW_Color(255,255,211,0)));
  superscena.push(paw);

  int a = 20;
  int b = -20;

  superscena.figs[0].rotate(PAW_Vector(120,290,0,0), a);
  superscena.figs[1].rotate(PAW_Vector(120,290,0,0), b);

  uint8_t i = 150;
  while(i--) {
	  HAL_GPIO_WritePin(GPIOG, GPIO_PIN_14, GPIO_PIN_SET);
	  superscena.display();

	  // nastrosz piorka
	  superscena.figs[0].rotate(PAW_Vector(120,290,0,0), a);
	  superscena.figs[1].rotate(PAW_Vector(120,290,0,0), b);

	  a = -1 * a;
	  b = -1 * b;
	  HAL_GPIO_WritePin(GPIOG, GPIO_PIN_14, GPIO_PIN_RESET);
	  HAL_GPIO_WritePin(GPIOG, GPIO_PIN_13, GPIO_PIN_SET);
	  HAL_Delay(1000);
	  HAL_GPIO_WritePin(GPIOG, GPIO_PIN_13, GPIO_PIN_RESET);
  }

  while (1)
  {
  /* USER CODE END WHILE */

  }

}

/** System Clock Configuration
*/
void SystemClock_Config(void)
{

  RCC_OscInitTypeDef RCC_OscInitStruct;
  RCC_ClkInitTypeDef RCC_ClkInitStruct;
  RCC_PeriphCLKInitTypeDef PeriphClkInitStruct;

    /**Configure the main internal regulator output voltage
    */
  __HAL_RCC_PWR_CLK_ENABLE();

  __HAL_PWR_VOLTAGESCALING_CONFIG(PWR_REGULATOR_VOLTAGE_SCALE1);

    /**Initializes the CPU, AHB and APB busses clocks
    */
  RCC_OscInitStruct.OscillatorType = RCC_OSCILLATORTYPE_HSE;
  RCC_OscInitStruct.HSEState = RCC_HSE_BYPASS;
  RCC_OscInitStruct.PLL.PLLState = RCC_PLL_ON;
  RCC_OscInitStruct.PLL.PLLSource = RCC_PLLSOURCE_HSE;
  RCC_OscInitStruct.PLL.PLLM = 8;
  RCC_OscInitStruct.PLL.PLLN = 360;
  RCC_OscInitStruct.PLL.PLLP = RCC_PLLP_DIV2;
  RCC_OscInitStruct.PLL.PLLQ = 7;
  if (HAL_RCC_OscConfig(&RCC_OscInitStruct) != HAL_OK)
  {
    Error_Handler();
  }

    /**Activate the Over-Drive mode
    */
  if (HAL_PWREx_EnableOverDrive() != HAL_OK)
  {
    Error_Handler();
  }

    /**Initializes the CPU, AHB and APB busses clocks
    */
  RCC_ClkInitStruct.ClockType = RCC_CLOCKTYPE_HCLK|RCC_CLOCKTYPE_SYSCLK
                              |RCC_CLOCKTYPE_PCLK1|RCC_CLOCKTYPE_PCLK2;
  RCC_ClkInitStruct.SYSCLKSource = RCC_SYSCLKSOURCE_PLLCLK;
  RCC_ClkInitStruct.AHBCLKDivider = RCC_SYSCLK_DIV1;
  RCC_ClkInitStruct.APB1CLKDivider = RCC_HCLK_DIV4;
  RCC_ClkInitStruct.APB2CLKDivider = RCC_HCLK_DIV2;

  if (HAL_RCC_ClockConfig(&RCC_ClkInitStruct, FLASH_LATENCY_5) != HAL_OK)
  {
    Error_Handler();
  }

  PeriphClkInitStruct.PeriphClockSelection = RCC_PERIPHCLK_LTDC;
  PeriphClkInitStruct.PLLSAI.PLLSAIN = 432;
  PeriphClkInitStruct.PLLSAI.PLLSAIR = 2;
  PeriphClkInitStruct.PLLSAIDivR = RCC_PLLSAIDIVR_2;
  if (HAL_RCCEx_PeriphCLKConfig(&PeriphClkInitStruct) != HAL_OK)
  {
    Error_Handler();
  }

    /**Configure the Systick interrupt time
    */
  HAL_SYSTICK_Config(HAL_RCC_GetHCLKFreq()/1000);

    /**Configure the Systick
    */
  HAL_SYSTICK_CLKSourceConfig(SYSTICK_CLKSOURCE_HCLK);

  /* SysTick_IRQn interrupt configuration */
  HAL_NVIC_SetPriority(SysTick_IRQn, 0, 0);
}

/* DMA2D init function */
static void MX_DMA2D_Init(void)
{

  hdma2d.Instance = DMA2D;
  hdma2d.Init.Mode = DMA2D_M2M;
  hdma2d.Init.ColorMode = DMA2D_OUTPUT_RGB565;
  hdma2d.Init.OutputOffset = 0;
  hdma2d.LayerCfg[1].InputOffset = 0;
  hdma2d.LayerCfg[1].InputColorMode = DMA2D_INPUT_RGB565;
  hdma2d.LayerCfg[1].AlphaMode = DMA2D_NO_MODIF_ALPHA;
  hdma2d.LayerCfg[1].InputAlpha = 0;
  if (HAL_DMA2D_Init(&hdma2d) != HAL_OK)
  {
    Error_Handler();
  }

  if (HAL_DMA2D_ConfigLayer(&hdma2d, 1) != HAL_OK)
  {
    Error_Handler();
  }

}

/* I2C3 init function */
static void MX_I2C3_Init(void)
{

  hi2c3.Instance = I2C3;
  hi2c3.Init.ClockSpeed = 100000;
  hi2c3.Init.DutyCycle = I2C_DUTYCYCLE_2;
  hi2c3.Init.OwnAddress1 = 0;
  hi2c3.Init.AddressingMode = I2C_ADDRESSINGMODE_7BIT;
  hi2c3.Init.DualAddressMode = I2C_DUALADDRESS_DISABLE;
  hi2c3.Init.OwnAddress2 = 0;
  hi2c3.Init.GeneralCallMode = I2C_GENERALCALL_DISABLE;
  hi2c3.Init.NoStretchMode = I2C_NOSTRETCH_DISABLE;
  if (HAL_I2C_Init(&hi2c3) != HAL_OK)
  {
    Error_Handler();
  }

}

/* LTDC init function */
static void MX_LTDC_Init(void)
{

  LTDC_LayerCfgTypeDef pLayerCfg;
  LTDC_LayerCfgTypeDef pLayerCfg1;

  hltdc.Instance = LTDC;
  hltdc.Init.HSPolarity = LTDC_HSPOLARITY_AL;
  hltdc.Init.VSPolarity = LTDC_VSPOLARITY_AL;
  hltdc.Init.DEPolarity = LTDC_DEPOLARITY_AL;
  hltdc.Init.PCPolarity = LTDC_PCPOLARITY_IPC;
  hltdc.Init.HorizontalSync = 7;
  hltdc.Init.VerticalSync = 3;
  hltdc.Init.AccumulatedHBP = 14;
  hltdc.Init.AccumulatedVBP = 5;
  hltdc.Init.AccumulatedActiveW = 334;
  hltdc.Init.AccumulatedActiveH = 485;
  hltdc.Init.TotalWidth = 340;
  hltdc.Init.TotalHeigh = 487;
  hltdc.Init.Backcolor.Blue = 0;
  hltdc.Init.Backcolor.Green = 0;
  hltdc.Init.Backcolor.Red = 0;
  if (HAL_LTDC_Init(&hltdc) != HAL_OK)
  {
    Error_Handler();
  }

  pLayerCfg.WindowX0 = 0;
  pLayerCfg.WindowX1 = 0;
  pLayerCfg.WindowY0 = 0;
  pLayerCfg.WindowY1 = 0;
  pLayerCfg.PixelFormat = LTDC_PIXEL_FORMAT_ARGB8888;
  pLayerCfg.Alpha = 0;
  pLayerCfg.Alpha0 = 0;
  pLayerCfg.BlendingFactor1 = LTDC_BLENDING_FACTOR1_CA;
  pLayerCfg.BlendingFactor2 = LTDC_BLENDING_FACTOR2_CA;
  pLayerCfg.FBStartAdress = 0;
  pLayerCfg.ImageWidth = 0;
  pLayerCfg.ImageHeight = 0;
  pLayerCfg.Backcolor.Blue = 0;
  pLayerCfg.Backcolor.Green = 0;
  pLayerCfg.Backcolor.Red = 0;
  if (HAL_LTDC_ConfigLayer(&hltdc, &pLayerCfg, 0) != HAL_OK)
  {
    Error_Handler();
  }

  pLayerCfg1.WindowX0 = 0;
  pLayerCfg1.WindowX1 = 0;
  pLayerCfg1.WindowY0 = 0;
  pLayerCfg1.WindowY1 = 0;
  pLayerCfg1.PixelFormat = LTDC_PIXEL_FORMAT_ARGB8888;
  pLayerCfg1.Alpha = 0;
  pLayerCfg1.Alpha0 = 0;
  pLayerCfg1.BlendingFactor1 = LTDC_BLENDING_FACTOR1_CA;
  pLayerCfg1.BlendingFactor2 = LTDC_BLENDING_FACTOR2_CA;
  pLayerCfg1.FBStartAdress = 0;
  pLayerCfg1.ImageWidth = 0;
  pLayerCfg1.ImageHeight = 0;
  pLayerCfg1.Backcolor.Blue = 0;
  pLayerCfg1.Backcolor.Green = 0;
  pLayerCfg1.Backcolor.Red = 0;
  if (HAL_LTDC_ConfigLayer(&hltdc, &pLayerCfg1, 1) != HAL_OK)
  {
    Error_Handler();
  }

}

/* SPI5 init function */
static void MX_SPI5_Init(void)
{

  hspi5.Instance = SPI5;
  hspi5.Init.Mode = SPI_MODE_MASTER;
  hspi5.Init.Direction = SPI_DIRECTION_2LINES;
  hspi5.Init.DataSize = SPI_DATASIZE_8BIT;
  hspi5.Init.CLKPolarity = SPI_POLARITY_LOW;
  hspi5.Init.CLKPhase = SPI_PHASE_1EDGE;
  hspi5.Init.NSS = SPI_NSS_SOFT;
  hspi5.Init.BaudRatePrescaler = SPI_BAUDRATEPRESCALER_2;
  hspi5.Init.FirstBit = SPI_FIRSTBIT_MSB;
  hspi5.Init.TIMode = SPI_TIMODE_DISABLE;
  hspi5.Init.CRCCalculation = SPI_CRCCALCULATION_DISABLE;
  hspi5.Init.CRCPolynomial = 10;
  if (HAL_SPI_Init(&hspi5) != HAL_OK)
  {
    Error_Handler();
  }

}
/* FMC initialization function */
static void MX_FMC_Init(void)
{
  FMC_SDRAM_TimingTypeDef SdramTiming;

  /** Perform the SDRAM1 memory initialization sequence
  */
  hsdram1.Instance = FMC_SDRAM_DEVICE;
  /* hsdram1.Init */
  hsdram1.Init.SDBank = FMC_SDRAM_BANK2;
  hsdram1.Init.ColumnBitsNumber = FMC_SDRAM_COLUMN_BITS_NUM_8;
  hsdram1.Init.RowBitsNumber = FMC_SDRAM_ROW_BITS_NUM_12;
  hsdram1.Init.MemoryDataWidth = FMC_SDRAM_MEM_BUS_WIDTH_16;
  hsdram1.Init.InternalBankNumber = FMC_SDRAM_INTERN_BANKS_NUM_4;
  hsdram1.Init.CASLatency = FMC_SDRAM_CAS_LATENCY_3;
  hsdram1.Init.WriteProtection = FMC_SDRAM_WRITE_PROTECTION_ENABLE;
  hsdram1.Init.SDClockPeriod = FMC_SDRAM_CLOCK_PERIOD_2;
  hsdram1.Init.ReadBurst = FMC_SDRAM_RBURST_DISABLE;
  hsdram1.Init.ReadPipeDelay = FMC_SDRAM_RPIPE_DELAY_2;
  /* SdramTiming */
  SdramTiming.LoadToActiveDelay = 16;
  SdramTiming.ExitSelfRefreshDelay = 16;
  SdramTiming.SelfRefreshTime = 16;
  SdramTiming.RowCycleDelay = 16;
  SdramTiming.WriteRecoveryTime = 16;
  SdramTiming.RPDelay = 16;
  SdramTiming.RCDDelay = 16;

  if (HAL_SDRAM_Init(&hsdram1, &SdramTiming) != HAL_OK)
  {
    Error_Handler();
  }

}

/** Configure pins as
        * Analog
        * Input
        * Output
        * EVENT_OUT
        * EXTI
     PB12   ------> USB_OTG_HS_ID
     PB13   ------> USB_OTG_HS_VBUS
     PB14   ------> USB_OTG_HS_DM
     PB15   ------> USB_OTG_HS_DP
*/
static void MX_GPIO_Init(void)
{

  GPIO_InitTypeDef GPIO_InitStruct;

  /* GPIO Ports Clock Enable */
  __HAL_RCC_GPIOC_CLK_ENABLE();
  __HAL_RCC_GPIOF_CLK_ENABLE();
  __HAL_RCC_GPIOH_CLK_ENABLE();
  __HAL_RCC_GPIOA_CLK_ENABLE();
  __HAL_RCC_GPIOB_CLK_ENABLE();
  __HAL_RCC_GPIOG_CLK_ENABLE();
  __HAL_RCC_GPIOE_CLK_ENABLE();
  __HAL_RCC_GPIOD_CLK_ENABLE();

  /*Configure GPIO pin Output Level */
  HAL_GPIO_WritePin(GPIOC, NCS_MEMS_SPI_Pin|CSX_Pin|OTG_FS_PSO_Pin, GPIO_PIN_RESET);

  /*Configure GPIO pin Output Level */
  HAL_GPIO_WritePin(ACP_RST_GPIO_Port, ACP_RST_Pin, GPIO_PIN_RESET);

  /*Configure GPIO pin Output Level */
  HAL_GPIO_WritePin(GPIOD, RDX_Pin|WRX_DCX_Pin, GPIO_PIN_RESET);

  /*Configure GPIO pin Output Level */
  HAL_GPIO_WritePin(GPIOG, LD3_Pin|LD4_Pin, GPIO_PIN_RESET);

  /*Configure GPIO pins : NCS_MEMS_SPI_Pin CSX_Pin OTG_FS_PSO_Pin */
  GPIO_InitStruct.Pin = NCS_MEMS_SPI_Pin|CSX_Pin|OTG_FS_PSO_Pin;
  GPIO_InitStruct.Mode = GPIO_MODE_OUTPUT_PP;
  GPIO_InitStruct.Pull = GPIO_NOPULL;
  GPIO_InitStruct.Speed = GPIO_SPEED_FREQ_LOW;
  HAL_GPIO_Init(GPIOC, &GPIO_InitStruct);

  /*Configure GPIO pins : B1_Pin MEMS_INT1_Pin MEMS_INT2_Pin TP_INT1_Pin */
  GPIO_InitStruct.Pin = B1_Pin|MEMS_INT1_Pin|MEMS_INT2_Pin|TP_INT1_Pin;
  GPIO_InitStruct.Mode = GPIO_MODE_EVT_RISING;
  GPIO_InitStruct.Pull = GPIO_NOPULL;
  HAL_GPIO_Init(GPIOA, &GPIO_InitStruct);

  /*Configure GPIO pin : ACP_RST_Pin */
  GPIO_InitStruct.Pin = ACP_RST_Pin;
  GPIO_InitStruct.Mode = GPIO_MODE_OUTPUT_PP;
  GPIO_InitStruct.Pull = GPIO_NOPULL;
  GPIO_InitStruct.Speed = GPIO_SPEED_FREQ_LOW;
  HAL_GPIO_Init(ACP_RST_GPIO_Port, &GPIO_InitStruct);

  /*Configure GPIO pin : OTG_FS_OC_Pin */
  GPIO_InitStruct.Pin = OTG_FS_OC_Pin;
  GPIO_InitStruct.Mode = GPIO_MODE_EVT_RISING;
  GPIO_InitStruct.Pull = GPIO_NOPULL;
  HAL_GPIO_Init(OTG_FS_OC_GPIO_Port, &GPIO_InitStruct);

  /*Configure GPIO pin : BOOT1_Pin */
  GPIO_InitStruct.Pin = BOOT1_Pin;
  GPIO_InitStruct.Mode = GPIO_MODE_INPUT;
  GPIO_InitStruct.Pull = GPIO_NOPULL;
  HAL_GPIO_Init(BOOT1_GPIO_Port, &GPIO_InitStruct);

  /*Configure GPIO pins : OTG_FS_ID_Pin OTG_FS_DM_Pin OTG_FS_DP_Pin */
  GPIO_InitStruct.Pin = OTG_FS_ID_Pin|OTG_FS_DM_Pin|OTG_FS_DP_Pin;
  GPIO_InitStruct.Mode = GPIO_MODE_AF_PP;
  GPIO_InitStruct.Pull = GPIO_NOPULL;
  GPIO_InitStruct.Speed = GPIO_SPEED_FREQ_LOW;
  GPIO_InitStruct.Alternate = GPIO_AF12_OTG_HS_FS;
  HAL_GPIO_Init(GPIOB, &GPIO_InitStruct);

  /*Configure GPIO pin : VBUS_FS_Pin */
  GPIO_InitStruct.Pin = VBUS_FS_Pin;
  GPIO_InitStruct.Mode = GPIO_MODE_INPUT;
  GPIO_InitStruct.Pull = GPIO_NOPULL;
  HAL_GPIO_Init(VBUS_FS_GPIO_Port, &GPIO_InitStruct);

  /*Configure GPIO pin : TE_Pin */
  GPIO_InitStruct.Pin = TE_Pin;
  GPIO_InitStruct.Mode = GPIO_MODE_INPUT;
  GPIO_InitStruct.Pull = GPIO_NOPULL;
  HAL_GPIO_Init(TE_GPIO_Port, &GPIO_InitStruct);

  /*Configure GPIO pins : RDX_Pin WRX_DCX_Pin */
  GPIO_InitStruct.Pin = RDX_Pin|WRX_DCX_Pin;
  GPIO_InitStruct.Mode = GPIO_MODE_OUTPUT_PP;
  GPIO_InitStruct.Pull = GPIO_NOPULL;
  GPIO_InitStruct.Speed = GPIO_SPEED_FREQ_LOW;
  HAL_GPIO_Init(GPIOD, &GPIO_InitStruct);

  /*Configure GPIO pins : LD3_Pin LD4_Pin */
  GPIO_InitStruct.Pin = LD3_Pin|LD4_Pin;
  GPIO_InitStruct.Mode = GPIO_MODE_OUTPUT_PP;
  GPIO_InitStruct.Pull = GPIO_NOPULL;
  GPIO_InitStruct.Speed = GPIO_SPEED_FREQ_LOW;
  HAL_GPIO_Init(GPIOG, &GPIO_InitStruct);

}

void Error_Handler(void)
{
  while(1)
  {
  }
}

/************************ (C) COPYRIGHT STMicroelectronics *****END OF FILE****/
